AUTOSAR XML (schema 4-2-2)
standard types defined: boolean, float32, uint8
package /ASW_COM_Pkg
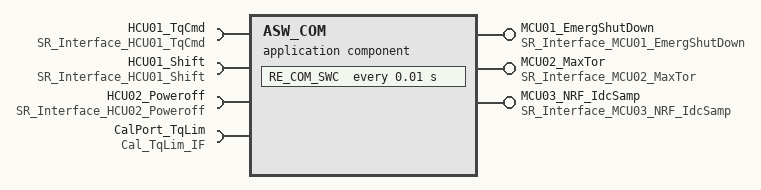
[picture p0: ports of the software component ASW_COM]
  application sw component type ASW_COM
    provide port MCU01_EmergShutDown: provided-interface=SR_Interface_MCU01_EmergShutDown
    provide port MCU02_MaxTor: provided-interface=SR_Interface_MCU02_MaxTor
    provide port MCU03_NRF_IdcSamp: provided-interface=SR_Interface_MCU03_NRF_IdcSamp
    4 x require port:
      HCU01_TqCmd: required-interface=SR_Interface_HCU01_TqCmd
      HCU01_Shift: required-interface=SR_Interface_HCU01_Shift
      HCU02_Poweroff: nonqueued-receiver-com-spec{data-element=Poweroff_DE, alive-timeout=0.3, init-value=0}, required-interface=SR_Interface_HCU02_Poweroff
      CalPort_TqLim: parameter-require-com-spec{parameter=TqLim_Val, alive-timeout=0.3, init-value=500}, required-interface=Cal_TqLim_IF
    behavior IB_ASW_COM
      timing event TE_RE_COM_SWC_10ms: start-on-event=RE_COM_SWC, period=0.01
      runnable RE_COM_SWC
        7 x access:
          VA_READ_HCU01_TqCmd: accessed-variable=HCU01_TqCmd.TqCmd_DE, access=READ
          VA_READ_HCU01_Shift: accessed-variable=HCU01_Shift.Shift_DE, access=READ
          VA_READ_HCU02_Poweroff: accessed-variable=HCU02_Poweroff.Poweroff_DE, access=READ
          VA_WRITE_MCU01_EmergShutDown: accessed-variable=MCU01_EmergShutDown.EmergShutDown_DE, access=WRITE
          VA_WRITE_MCU02_MaxTor: accessed-variable=MCU02_MaxTor.MaxTor_DE, access=WRITE
          VA_WRITE_MCU03_NRF_IdcSamp: accessed-variable=MCU03_NRF_IdcSamp.IdcSamp_DE, access=WRITE
          VA_PARAM_CalPort_TqLim: accessed-variable=CalPort_TqLim.TqLim_Val, access=READ
package /COM_Interface
  6 x sender receiver interface:
    SR_Interface_MCU01_EmergShutDown
      data EmergShutDown_DE: type=Impl_Boolean
    SR_Interface_MCU02_MaxTor
      data MaxTor_DE: type=Impl_Float
    SR_Interface_MCU03_NRF_IdcSamp
      data IdcSamp_DE: type=Impl_Float
    SR_Interface_HCU01_TqCmd
      data TqCmd_DE: type=Impl_Float
    SR_Interface_HCU01_Shift
      data Shift_DE: type=Impl_Uint8
    SR_Interface_HCU02_Poweroff
      data Poweroff_DE: type=Impl_Boolean
  parameter interface Cal_TqLim_IF
    parameter data prototype TqLim_Val: type=Impl_Float
package /DataTypes
  impl type Impl_Boolean: category=VALUE, base-type=boolean
  impl type Impl_Float: category=VALUE, base-type=float32
  impl type Impl_Uint8: category=VALUE, base-type=uint8
